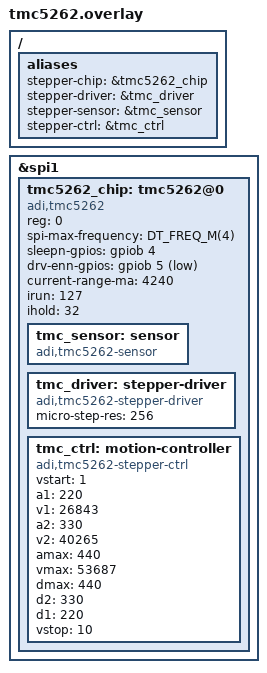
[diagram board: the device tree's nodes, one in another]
/*
 * SPDX-FileCopyrightText: Copyright (c) 2026 Analog Devices, Inc.
 * SPDX-License-Identifier: Apache-2.0
 */

/* TMC5262: internal ramp generator is the step source */

/ {
	aliases {
		stepper-chip = &tmc5262_chip;
		stepper-driver = &tmc_driver;
		stepper-sensor = &tmc_sensor;
		stepper-ctrl = &tmc_ctrl;
	};
};

&spi1 {
	tmc5262_chip: tmc5262@0 {
		compatible = "adi,tmc5262";
		reg = <0>;
		spi-max-frequency = <DT_FREQ_M(4)>;
		sleepn-gpios = <&gpiob 4 GPIO_ACTIVE_HIGH>;
		drv-enn-gpios = <&gpiob 5 GPIO_ACTIVE_LOW>;

		/* 4.24 A RMS (6 A peak) range, run at about 50 percent */
		current-range-ma = <4240>;
		irun = <127>;
		ihold = <32>;

		tmc_sensor: sensor {
			compatible = "adi,tmc5262-sensor";
		};

		tmc_driver: stepper-driver {
			compatible = "adi,tmc5262-stepper-driver";
			micro-step-res = <256>;
		};

		tmc_ctrl: motion-controller {
			compatible = "adi,tmc5262-stepper-ctrl";
			vstart = <1>;
			a1 = <220>;
			v1 = <26843>;
			a2 = <330>;
			v2 = <40265>;
			amax = <440>;
			vmax = <53687>;
			dmax = <440>;
			d2 = <330>;
			d1 = <220>;
			vstop = <10>;
		};
	};
};
